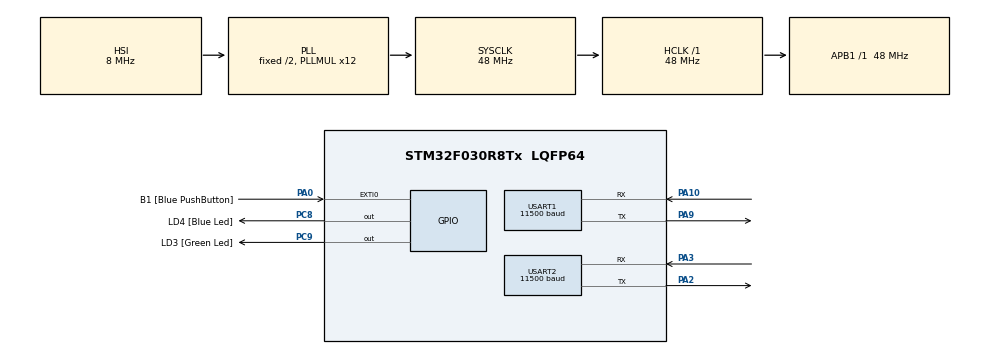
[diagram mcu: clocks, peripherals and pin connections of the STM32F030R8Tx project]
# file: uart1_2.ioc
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Dma.Request0=USART1_RX
Dma.Request1=USART1_TX
Dma.Request2=USART2_RX
Dma.Request3=USART2_TX
Dma.USART1_RX.0.Direction=DMA_PERIPH_TO_MEMORY
Dma.USART1_RX.0.Instance=DMA1_Channel3
Dma.USART1_RX.0.MemDataAlignment=DMA_MDATAALIGN_WORD
Dma.USART1_RX.0.MemInc=DMA_MINC_ENABLE
Dma.USART1_RX.0.Mode=DMA_CIRCULAR
Dma.USART1_RX.0.PeriphDataAlignment=DMA_PDATAALIGN_WORD
Dma.USART1_RX.0.PeriphInc=DMA_PINC_ENABLE
Dma.USART1_RX.0.Priority=DMA_PRIORITY_HIGH
Dma.USART1_TX.1.Direction=DMA_MEMORY_TO_PERIPH
Dma.USART1_TX.1.Instance=DMA1_Channel2
Dma.USART1_TX.1.MemDataAlignment=DMA_MDATAALIGN_BYTE
Dma.USART1_TX.1.MemInc=DMA_MINC_DISABLE
Dma.USART1_TX.1.Mode=DMA_NORMAL
Dma.USART1_TX.1.PeriphDataAlignment=DMA_PDATAALIGN_BYTE
Dma.USART1_TX.1.PeriphInc=DMA_PINC_DISABLE
Dma.USART1_TX.1.Priority=DMA_PRIORITY_HIGH
Dma.USART2_RX.2.Direction=DMA_PERIPH_TO_MEMORY
Dma.USART2_RX.2.Instance=DMA1_Channel5
Dma.USART2_RX.2.MemDataAlignment=DMA_MDATAALIGN_BYTE
Dma.USART2_RX.2.MemInc=DMA_MINC_DISABLE
Dma.USART2_RX.2.Mode=DMA_NORMAL
Dma.USART2_RX.2.PeriphDataAlignment=DMA_PDATAALIGN_BYTE
Dma.USART2_RX.2.PeriphInc=DMA_PINC_DISABLE
Dma.USART2_RX.2.Priority=DMA_PRIORITY_HIGH
Dma.USART2_TX.3.Direction=DMA_MEMORY_TO_PERIPH
Dma.USART2_TX.3.Instance=DMA1_Channel4
Dma.USART2_TX.3.MemDataAlignment=DMA_MDATAALIGN_WORD
Dma.USART2_TX.3.MemInc=DMA_MINC_ENABLE
Dma.USART2_TX.3.Mode=DMA_CIRCULAR
Dma.USART2_TX.3.PeriphDataAlignment=DMA_PDATAALIGN_WORD
Dma.USART2_TX.3.PeriphInc=DMA_PINC_ENABLE
Dma.USART2_TX.3.Priority=DMA_PRIORITY_HIGH
FREERTOS.Tasks01=UartTask1,0,128,StartDefaultTask;UartTask2,-3,128,StartTask02
Mcu.Family=STM32F0
Mcu.Name=STM32F030R8Tx
Mcu.Package=LQFP64
NVIC.DMA1_Channel2_3_IRQn=true\:3\:0\:false
NVIC.DMA1_Channel4_5_IRQn=true\:3\:0\:false
NVIC.USART1_IRQn=true\:3\:0\:false
NVIC.USART2_IRQn=true\:3\:0\:false
PA0.GPIO_Label=B1 [Blue PushButton]
PA0.GPIO_ModeDefaultEXTI=GPIO_MODE_EVT_RISING
PA0.GPIO_PuPd=GPIO_NOPULL
PA0.Signal=GPXTI0
PA10.Mode=Asynchronous
PA10.Signal=USART1_RX
PA13.GPIO_Label=SWDIO
PA13.Mode=Serial-WireDebug
PA13.Signal=SYS_SWDIO
PA14.GPIO_Label=SWCLK
PA14.Mode=Serial-WireDebug
PA14.Signal=SYS_SWCLK
PA2.Mode=Asynchronous
PA2.Signal=USART2_TX
PA3.Mode=Asynchronous
PA3.Signal=USART2_RX
PA9.Mode=Asynchronous
PA9.Signal=USART1_TX
PC8.GPIO_Label=LD4 [Blue Led]
PC8.GPIO_ModeDefaultOutputPP=GPIO_MODE_OUTPUT_PP
PC8.GPIO_PuPd=GPIO_NOPULL
PC8.GPIO_Speed=GPIO_SPEED_LOW
PC8.Signal=GPIO_Output
PC9.GPIO_Label=LD3 [Green Led]
PC9.GPIO_ModeDefaultOutputPP=GPIO_MODE_OUTPUT_PP
PC9.GPIO_PuPd=GPIO_NOPULL
PC9.GPIO_Speed=GPIO_SPEED_LOW
PC9.Signal=GPIO_Output
ProjectManager.TargetToolchain=MDK-ARM V5
RCC.AHBFreq_Value=48000000
RCC.APB1Freq_Value=48000000
RCC.APB1TimFreq_Value=48000000
RCC.HCLKFreq_Value=48000000
RCC.PLLMUL=RCC_PLL_MUL12
RCC.SYSCLKFreq_VALUE=48000000
RCC.SYSCLKSource=RCC_SYSCLKSOURCE_PLLCLK
USART1.BaudRate=11500
USART2.BaudRate=11500
VP_CRC_VS_CRC.Mode=CRC_Activate
VP_FREERTOS_VS_ENABLE.Mode=Enabled

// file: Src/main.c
/**
  ******************************************************************************
  * File Name          : main.c
  * Date               : 01/11/2015 18:09:33
  * Description        : Main program body
  ******************************************************************************
  *
  * COPYRIGHT(c) 2015 STMicroelectronics
  *
  * Redistribution and use in source and binary forms, with or without modification,
  * are permitted provided that the following conditions are met:
  *   1. Redistributions of source code must retain the above copyright notice,
  *      this list of conditions and the following disclaimer.
  *   2. Redistributions in binary form must reproduce the above copyright notice,
  *      this list of conditions and the following disclaimer in the documentation
  *      and/or other materials provided with the distribution.
  *   3. Neither the name of STMicroelectronics nor the names of its contributors
  *      may be used to endorse or promote products derived from this software
  *      without specific prior written permission.
  *
  * THIS SOFTWARE IS PROVIDED BY THE COPYRIGHT HOLDERS AND CONTRIBUTORS "AS IS"
  * AND ANY EXPRESS OR IMPLIED WARRANTIES, INCLUDING, BUT NOT LIMITED TO, THE
  * IMPLIED WARRANTIES OF MERCHANTABILITY AND FITNESS FOR A PARTICULAR PURPOSE ARE
  * DISCLAIMED. IN NO EVENT SHALL THE COPYRIGHT HOLDER OR CONTRIBUTORS BE LIABLE
  * FOR ANY DIRECT, INDIRECT, INCIDENTAL, SPECIAL, EXEMPLARY, OR CONSEQUENTIAL
  * DAMAGES (INCLUDING, BUT NOT LIMITED TO, PROCUREMENT OF SUBSTITUTE GOODS OR
  * SERVICES; LOSS OF USE, DATA, OR PROFITS; OR BUSINESS INTERRUPTION) HOWEVER
  * CAUSED AND ON ANY THEORY OF LIABILITY, WHETHER IN CONTRACT, STRICT LIABILITY,
  * OR TORT (INCLUDING NEGLIGENCE OR OTHERWISE) ARISING IN ANY WAY OUT OF THE USE
  * OF THIS SOFTWARE, EVEN IF ADVISED OF THE POSSIBILITY OF SUCH DAMAGE.
  *
  ******************************************************************************
  */

#include "stm32f0xx_hal.h"
#include "cmsis_os.h"
#include "stdio.h"
#include "Board_Buttons.h"              // ::Board Support:Buttons

/*
#ifdef __GNUC__
	#define PUTCHAR_PROTOTYPE int __io_putchar(int ch)
	#define GETCHAR_PROTOTYPE int __io_getchar(int chr)
#else
	#define PUTCHAR_PROTOTYPE int fputc(int tx_byte,FILE *f)
	#define GETCHAR_PROTOTYPE int fgetc(FILE *f)
#endif

 */
int rx_byte=0;
CRC_HandleTypeDef hcrc;

UART_HandleTypeDef huart1;
UART_HandleTypeDef huart2;
DMA_HandleTypeDef hdma_usart1_rx;
DMA_HandleTypeDef hdma_usart1_tx;
DMA_HandleTypeDef hdma_usart2_rx;
DMA_HandleTypeDef hdma_usart2_tx;

osThreadId UartTask1Handle;
osThreadId UartTask2Handle;

/*
GETCHAR_PROTOTYPE
{
	HAL_UART_Receive_DMA(&huart1,(uint8_t *)&rx_byte,2);
	HAL_UART_Receive_DMA(&huart2,(uint8_t *)&rx_byte,2);
	return rx_byte;
}

PUTCHAR_PROTOTYPE
 {
	 //HAL_UART_Transmit(&huart1,(uint8_t *)&ch,1,0xFFFF);

	 HAL_UART_Transmit_DMA(&huart1,(uint8_t *)&tx_byte,2);
	 HAL_UART_Transmit_DMA(&huart2,(uint8_t *)&tx_byte,2);

	 return tx_byte;
 }
 */

void SystemClock_Config(void);
static void MX_GPIO_Init(void);
static void MX_DMA_Init(void);
static void MX_CRC_Init(void);
static void MX_USART1_UART_Init(void);
static void MX_USART2_UART_Init(void);
void StartDefaultTask(void const * argument);
void StartTask02(void const * argument);

int main(void)
{

  /* MCU Configuration----------------------------------------------------------*/

  /* Reset of all peripherals, Initializes the Flash interface and the Systick. */
  HAL_Init();

  /* Configure the system clock */
  SystemClock_Config();
	Buttons_Initialize();
  /* Initialize all configured peripherals */
  MX_GPIO_Init();
  MX_DMA_Init();
  MX_CRC_Init();
  MX_USART1_UART_Init();
  MX_USART2_UART_Init();

  /* Create the thread(s) */
  /* definition and creation of UartTask1 */
  osThreadDef(UartTask1, StartDefaultTask, osPriorityNormal, 0, 128);
  UartTask1Handle = osThreadCreate(osThread(UartTask1), NULL);

  /* definition and creation of UartTask2 */
  osThreadDef(UartTask2, StartTask02, osPriorityIdle, 0, 128);
  UartTask2Handle = osThreadCreate(osThread(UartTask2), NULL);

  /* Start scheduler */
  osKernelStart();

  /* We should never get here as control is now taken by the scheduler */

  /* Infinite loop */
  while (1)
  {

  }

}

/** System Clock Configuration
*/
void SystemClock_Config(void)
{

  RCC_OscInitTypeDef RCC_OscInitStruct;
  RCC_ClkInitTypeDef RCC_ClkInitStruct;
  RCC_PeriphCLKInitTypeDef PeriphClkInit;

  RCC_OscInitStruct.OscillatorType = RCC_OSCILLATORTYPE_HSI;
  RCC_OscInitStruct.HSIState = RCC_HSI_ON;
  RCC_OscInitStruct.HSICalibrationValue = 16;
  RCC_OscInitStruct.PLL.PLLState = RCC_PLL_ON;
  RCC_OscInitStruct.PLL.PLLSource = RCC_PLLSOURCE_HSI;
  RCC_OscInitStruct.PLL.PLLMUL = RCC_PLL_MUL12;
  RCC_OscInitStruct.PLL.PREDIV = RCC_PREDIV_DIV1;
  HAL_RCC_OscConfig(&RCC_OscInitStruct);

  RCC_ClkInitStruct.ClockType = RCC_CLOCKTYPE_SYSCLK;
  RCC_ClkInitStruct.SYSCLKSource = RCC_SYSCLKSOURCE_PLLCLK;
  RCC_ClkInitStruct.AHBCLKDivider = RCC_SYSCLK_DIV1;
  RCC_ClkInitStruct.APB1CLKDivider = RCC_HCLK_DIV1;
  HAL_RCC_ClockConfig(&RCC_ClkInitStruct, FLASH_LATENCY_1);

  PeriphClkInit.PeriphClockSelection = RCC_PERIPHCLK_USART1;
  PeriphClkInit.Usart1ClockSelection = RCC_USART1CLKSOURCE_PCLK1;
  HAL_RCCEx_PeriphCLKConfig(&PeriphClkInit);

  __SYSCFG_CLK_ENABLE();

}

/* CRC init function */
void MX_CRC_Init(void)
{

  hcrc.Instance = CRC;
  hcrc.Init.DefaultPolynomialUse = DEFAULT_POLYNOMIAL_ENABLE;
  hcrc.Init.DefaultInitValueUse = DEFAULT_INIT_VALUE_ENABLE;
  hcrc.Init.InputDataInversionMode = CRC_INPUTDATA_INVERSION_NONE;
  hcrc.Init.OutputDataInversionMode = CRC_OUTPUTDATA_INVERSION_DISABLED;
  hcrc.InputDataFormat = CRC_INPUTDATA_FORMAT_BYTES;
  HAL_CRC_Init(&hcrc);

}

/* USART1 init function */
void MX_USART1_UART_Init(void)
{

  huart1.Instance = USART1;
  huart1.Init.BaudRate = 9600;
  huart1.Init.WordLength = UART_WORDLENGTH_8B;
  huart1.Init.StopBits = UART_STOPBITS_1;
  huart1.Init.Parity = UART_PARITY_NONE;
  huart1.Init.Mode = UART_MODE_TX_RX;
  huart1.Init.HwFlowCtl = UART_HWCONTROL_NONE;
  huart1.Init.OverSampling = UART_OVERSAMPLING_16;
  huart1.Init.OneBitSampling = UART_ONEBIT_SAMPLING_DISABLED ;
  huart1.AdvancedInit.AdvFeatureInit = UART_ADVFEATURE_NO_INIT;
  HAL_UART_Init(&huart1);

}

/* USART2 init function */
void MX_USART2_UART_Init(void)
{

  huart2.Instance = USART2;
  huart2.Init.BaudRate = 9600;
  huart2.Init.WordLength = UART_WORDLENGTH_8B;
  huart2.Init.StopBits = UART_STOPBITS_1;
  huart2.Init.Parity = UART_PARITY_NONE;
  huart2.Init.Mode = UART_MODE_TX_RX;
  huart2.Init.HwFlowCtl = UART_HWCONTROL_NONE;
  huart2.Init.OverSampling = UART_OVERSAMPLING_16;
  huart2.Init.OneBitSampling = UART_ONEBIT_SAMPLING_DISABLED ;
  huart2.AdvancedInit.AdvFeatureInit = UART_ADVFEATURE_NO_INIT;
  HAL_UART_Init(&huart2);

}

void MX_DMA_Init(void)
{
  /* DMA controller clock enable */
  __DMA1_CLK_ENABLE();

  /* DMA interrupt init */
  HAL_NVIC_SetPriority(DMA1_Channel2_3_IRQn, 3, 0);
  HAL_NVIC_EnableIRQ(DMA1_Channel2_3_IRQn);
  HAL_NVIC_SetPriority(DMA1_Channel4_5_IRQn, 3, 0);
  HAL_NVIC_EnableIRQ(DMA1_Channel4_5_IRQn);

}

/** Configure pins as
        * Analog
        * Input
        * Output
        * EVENT_OUT
        * EXTI
*/
void MX_GPIO_Init(void)
{

  GPIO_InitTypeDef GPIO_InitStruct;

  /* GPIO Ports Clock Enable */
  __GPIOA_CLK_ENABLE();
  __GPIOC_CLK_ENABLE();

  /*Configure GPIO pin : PA0 */
  GPIO_InitStruct.Pin = GPIO_PIN_0;
  GPIO_InitStruct.Mode = GPIO_MODE_EVT_RISING;
  GPIO_InitStruct.Pull = GPIO_NOPULL;
  HAL_GPIO_Init(GPIOA, &GPIO_InitStruct);

  /*Configure GPIO pins : PC8 PC9 */
  GPIO_InitStruct.Pin = GPIO_PIN_8|GPIO_PIN_9;
  GPIO_InitStruct.Mode = GPIO_MODE_OUTPUT_PP;
  GPIO_InitStruct.Pull = GPIO_NOPULL;
  GPIO_InitStruct.Speed = GPIO_SPEED_LOW;
  HAL_GPIO_Init(GPIOC, &GPIO_InitStruct);

}

/* StartDefaultTask function */
void StartDefaultTask(void const * argument)
{
char a=97;

  /* USER CODE BEGIN 5 */
  /* Infinite loop */
  for(;;)
  {
		if(HAL_UART_Receive_DMA(&huart1,(uint8_t *)&rx_byte,1)==0){
			switch(rx_byte){
				case 0: a=Buttons_GetState();
							  HAL_UART_Transmit_DMA(&huart1,(uint8_t *)&a,1);
								break;

				case 1: HAL_UART_Receive_DMA(&huart2,(uint8_t *)&rx_byte,1);
								a=rx_byte;
								HAL_UART_Transmit_DMA(&huart1,(uint8_t *)&a,1);
								break;
			}
		}

		HAL_UART_Transmit_DMA(&huart1,(uint8_t *)&a,1);
    osDelay(100);
  }
  /* USER CODE END 5 */
}

/* StartTask02 function */
void StartTask02(void const * argument)
{
  for(;;)
  {
    osDelay(1);
  }
}

/************************ (C) COPYRIGHT STMicroelectronics *****END OF FILE****/
